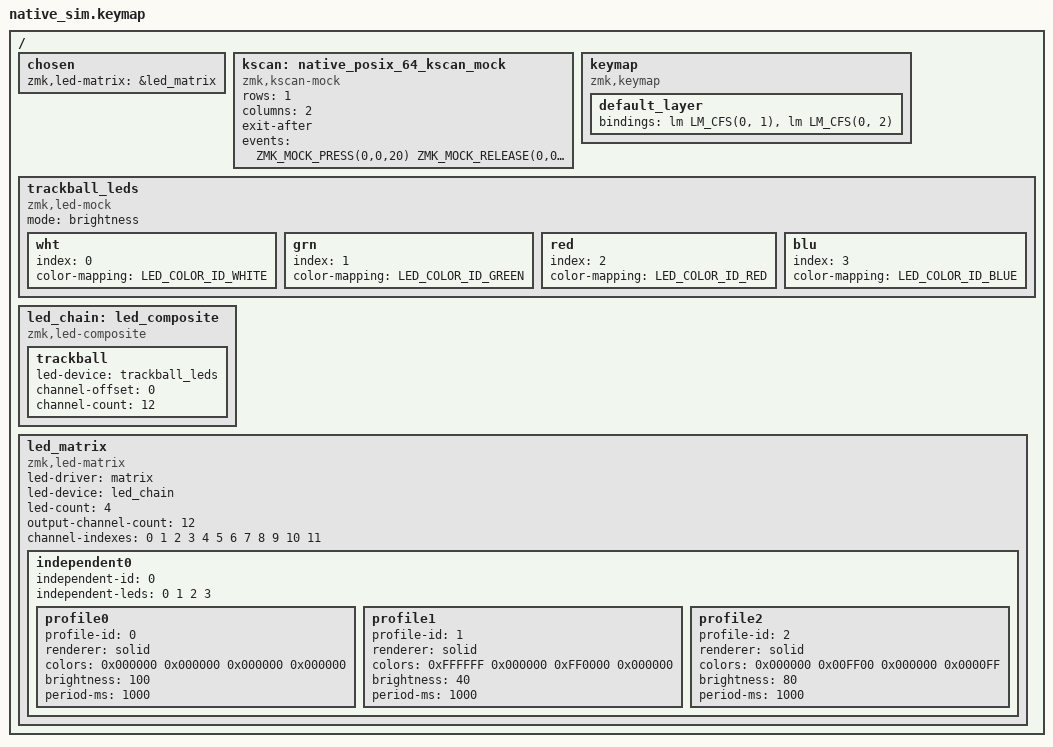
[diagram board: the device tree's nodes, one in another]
#include <dt-bindings/led/led.h>
#include <dt-bindings/zmk/kscan_mock.h>
#include <dt-bindings/zmk/led_matrix.h>
#include <behaviors.dtsi>

/ {
    chosen {
        zmk,led-matrix = &led_matrix;
    };

    kscan: native_posix_64_kscan_mock {
        compatible = "zmk,kscan-mock";
        rows = <1>;
        columns = <2>;
        exit-after;
        events = <
            ZMK_MOCK_PRESS(0,0,20)
            ZMK_MOCK_RELEASE(0,0,20)
            ZMK_MOCK_PRESS(0,1,20)
            ZMK_MOCK_RELEASE(0,1,20)
        >;
    };

    keymap {
        compatible = "zmk,keymap";

        default_layer {
            bindings = <
                &lm LM_CFS(0, 1)
                &lm LM_CFS(0, 2)
            >;
        };
    };

    trackball_leds: trackball_leds {
        compatible = "zmk,led-mock";
        mode = "brightness";

        wht { index = <0>; color-mapping = <LED_COLOR_ID_WHITE>; };
        grn { index = <1>; color-mapping = <LED_COLOR_ID_GREEN>; };
        red { index = <2>; color-mapping = <LED_COLOR_ID_RED>; };
        blu { index = <3>; color-mapping = <LED_COLOR_ID_BLUE>; };
    };

    led_chain: led_composite {
        compatible = "zmk,led-composite";

        trackball {
            led-device = <&trackball_leds>;
            channel-offset = <0>;
            channel-count = <12>;
        };
    };

    led_matrix: led_matrix {
        compatible = "zmk,led-matrix";
        led-driver = "matrix";
        led-device = <&led_chain>;
        led-count = <4>;
        output-channel-count = <12>;
        channel-indexes = <
            0 1 2
            3 4 5
            6 7 8
            9 10 11
        >;

        independent0 {
            independent-id = <0>;
            independent-leds = <0 1 2 3>;

            profile0 {
                profile-id = <0>;
                renderer = "solid";
                colors = <0x000000 0x000000 0x000000 0x000000>;
                brightness = <100>;
                period-ms = <1000>;
            };

            profile1 {
                profile-id = <1>;
                renderer = "solid";
                colors = <0xFFFFFF 0x000000 0xFF0000 0x000000>;
                brightness = <40>;
                period-ms = <1000>;
            };

            profile2 {
                profile-id = <2>;
                renderer = "solid";
                colors = <0x000000 0x00FF00 0x000000 0x0000FF>;
                brightness = <80>;
                period-ms = <1000>;
            };
        };
    };
};

